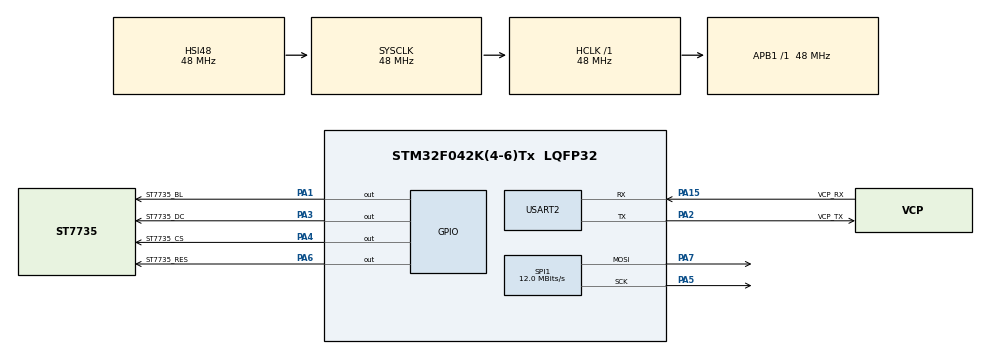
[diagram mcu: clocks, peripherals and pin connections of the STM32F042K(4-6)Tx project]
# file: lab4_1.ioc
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Mcu.Family=STM32F0
Mcu.Name=STM32F042K(4-6)Tx
Mcu.Package=LQFP32
PA1.GPIO_Label=ST7735_BL
PA1.Signal=GPIO_Output
PA13.GPIO_Label=SWDIO
PA13.Mode=Serial_Wire
PA13.Signal=SYS_SWDIO
PA14.GPIO_Label=SWCLK
PA14.Mode=Serial_Wire
PA14.Signal=SYS_SWCLK
PA15.GPIO_Label=VCP_RX
PA15.Mode=Asynchronous
PA15.Signal=USART2_RX
PA2.GPIO_Label=VCP_TX
PA2.Mode=Asynchronous
PA2.Signal=USART2_TX
PA3.GPIO_Label=ST7735_DC
PA3.Signal=GPIO_Output
PA4.GPIO_Label=ST7735_CS
PA4.Signal=GPIO_Output
PA5.Mode=TX_Only_Simplex_Unidirect_Master
PA5.Signal=SPI1_SCK
PA6.GPIO_Label=ST7735_RES
PA6.Signal=GPIO_Output
PA7.Mode=TX_Only_Simplex_Unidirect_Master
PA7.Signal=SPI1_MOSI
PF0-OSC_IN.GPIO_Label=MCO
PF0-OSC_IN.Mode=HSE-External-Clock-Source
PF0-OSC_IN.Signal=RCC_OSC_IN
ProjectManager.HeapSize=0x200
ProjectManager.StackSize=0x400
ProjectManager.TargetToolchain=STM32CubeIDE
RCC.AHBFreq_Value=48000000
RCC.APB1Freq_Value=48000000
RCC.APB1TimFreq_Value=48000000
RCC.HCLKFreq_Value=48000000
RCC.SYSCLKFreq_VALUE=48000000
RCC.SYSCLKSource=RCC_SYSCLKSOURCE_HSI48
SPI1.BaudRatePrescaler=SPI_BAUDRATEPRESCALER_4
SPI1.CalculateBaudRate=12.0 MBits/s
SPI1.DataSize=SPI_DATASIZE_8BIT
SPI1.Direction=SPI_DIRECTION_2LINES
SPI1.Mode=SPI_MODE_MASTER
SPI1.VirtualType=VM_MASTER
USART2.VirtualMode-Asynchronous=VM_ASYNC
board=NUCLEO-F042K6

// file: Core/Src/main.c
/* USER CODE BEGIN Header */
/**
  ******************************************************************************
  * @file           : main.c
  * @brief          : Main program body
  ******************************************************************************
  * @attention
  *
  * Copyright (c) 2025 STMicroelectronics.
  * All rights reserved.
  *
  * This software is licensed under terms that can be found in the LICENSE file
  * in the root directory of this software component.
  * If no LICENSE file comes with this software, it is provided AS-IS.
  *
  ******************************************************************************
  */
/* USER CODE END Header */
#include "main.h"
#include "st7735.h"
#include "fonts.h"

SPI_HandleTypeDef hspi1;

UART_HandleTypeDef huart2;

void SystemClock_Config(void);
static void MX_GPIO_Init(void);
static void MX_USART2_UART_Init(void);
static void MX_SPI1_Init(void);

int main(void)
{

  /* MCU Configuration--------------------------------------------------------*/

  /* Reset of all peripherals, Initializes the Flash interface and the Systick. */
  HAL_Init();

  /* Configure the system clock */
  SystemClock_Config();

  /* Initialize all configured peripherals */
  MX_GPIO_Init();
  MX_USART2_UART_Init();
  MX_SPI1_Init();
  /* USER CODE BEGIN 2 */
  ST7735_Init();
  ST7735_Backlight_On();
  ST7735_FillScreen(ST7735_BLACK);
  ST7735_DrawString(0, 0, "Hello World", Font_11x18, ST7735_WHITE, ST7735_BLACK );
  /* USER CODE END 2 */

  /* Infinite loop */
  while (1)
  {

  }
}

void SystemClock_Config(void)
{
  RCC_OscInitTypeDef RCC_OscInitStruct = {0};
  RCC_ClkInitTypeDef RCC_ClkInitStruct = {0};

  /** Initializes the RCC Oscillators according to the specified parameters
  * in the RCC_OscInitTypeDef structure.
  */
  RCC_OscInitStruct.OscillatorType = RCC_OSCILLATORTYPE_HSI48;
  RCC_OscInitStruct.HSI48State = RCC_HSI48_ON;
  RCC_OscInitStruct.PLL.PLLState = RCC_PLL_NONE;
  if (HAL_RCC_OscConfig(&RCC_OscInitStruct) != HAL_OK)
  {
    Error_Handler();
  }

  /** Initializes the CPU, AHB and APB buses clocks
  */
  RCC_ClkInitStruct.ClockType = RCC_CLOCKTYPE_HCLK|RCC_CLOCKTYPE_SYSCLK
                              |RCC_CLOCKTYPE_PCLK1;
  RCC_ClkInitStruct.SYSCLKSource = RCC_SYSCLKSOURCE_HSI48;
  RCC_ClkInitStruct.AHBCLKDivider = RCC_SYSCLK_DIV1;
  RCC_ClkInitStruct.APB1CLKDivider = RCC_HCLK_DIV1;

  if (HAL_RCC_ClockConfig(&RCC_ClkInitStruct, FLASH_LATENCY_1) != HAL_OK)
  {
    Error_Handler();
  }
}

static void MX_SPI1_Init(void)
{

  /* SPI1 parameter configuration*/
  hspi1.Instance = SPI1;
  hspi1.Init.Mode = SPI_MODE_MASTER;
  hspi1.Init.Direction = SPI_DIRECTION_2LINES;
  hspi1.Init.DataSize = SPI_DATASIZE_8BIT;
  hspi1.Init.CLKPolarity = SPI_POLARITY_LOW;
  hspi1.Init.CLKPhase = SPI_PHASE_1EDGE;
  hspi1.Init.NSS = SPI_NSS_SOFT;
  hspi1.Init.BaudRatePrescaler = SPI_BAUDRATEPRESCALER_4;
  hspi1.Init.FirstBit = SPI_FIRSTBIT_MSB;
  hspi1.Init.TIMode = SPI_TIMODE_DISABLE;
  hspi1.Init.CRCCalculation = SPI_CRCCALCULATION_DISABLE;
  hspi1.Init.CRCPolynomial = 7;
  hspi1.Init.CRCLength = SPI_CRC_LENGTH_DATASIZE;
  hspi1.Init.NSSPMode = SPI_NSS_PULSE_ENABLE;
  if (HAL_SPI_Init(&hspi1) != HAL_OK)
  {
    Error_Handler();
  }

}

static void MX_USART2_UART_Init(void)
{

  huart2.Instance = USART2;
  huart2.Init.BaudRate = 38400;
  huart2.Init.WordLength = UART_WORDLENGTH_8B;
  huart2.Init.StopBits = UART_STOPBITS_1;
  huart2.Init.Parity = UART_PARITY_NONE;
  huart2.Init.Mode = UART_MODE_TX_RX;
  huart2.Init.HwFlowCtl = UART_HWCONTROL_NONE;
  huart2.Init.OverSampling = UART_OVERSAMPLING_16;
  huart2.Init.OneBitSampling = UART_ONE_BIT_SAMPLE_DISABLE;
  huart2.AdvancedInit.AdvFeatureInit = UART_ADVFEATURE_NO_INIT;
  if (HAL_UART_Init(&huart2) != HAL_OK)
  {
    Error_Handler();
  }

}

static void MX_GPIO_Init(void)
{
  GPIO_InitTypeDef GPIO_InitStruct = {0};

  /* GPIO Ports Clock Enable */
  __HAL_RCC_GPIOF_CLK_ENABLE();
  __HAL_RCC_GPIOA_CLK_ENABLE();

  /*Configure GPIO pin Output Level */
  HAL_GPIO_WritePin(GPIOA, ST7735_BL_Pin|ST7735_DC_Pin|ST7735_CS_Pin|ST7735_RES_Pin, GPIO_PIN_RESET);

  /*Configure GPIO pins : ST7735_BL_Pin ST7735_DC_Pin ST7735_CS_Pin ST7735_RES_Pin */
  GPIO_InitStruct.Pin = ST7735_BL_Pin|ST7735_DC_Pin|ST7735_CS_Pin|ST7735_RES_Pin;
  GPIO_InitStruct.Mode = GPIO_MODE_OUTPUT_PP;
  GPIO_InitStruct.Pull = GPIO_NOPULL;
  GPIO_InitStruct.Speed = GPIO_SPEED_FREQ_LOW;
  HAL_GPIO_Init(GPIOA, &GPIO_InitStruct);

}

void Error_Handler(void)
{
  __disable_irq();
  while (1)
  {
  }
}
